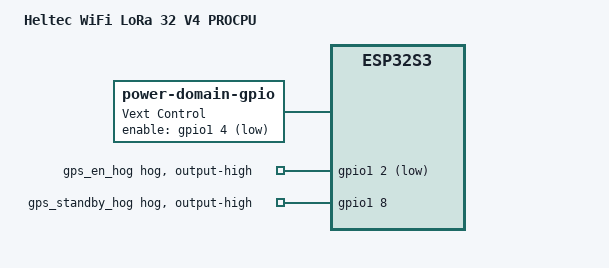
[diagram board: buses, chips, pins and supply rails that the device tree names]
/*
 * Heltec WiFi LoRa 32 (V4) — PROCPU, revisions 4.2 and 4.3.
 * ESP32-S3 WROOM, 16MB flash + 2MB QSPI PSRAM.
 *
 * SPDX-License-Identifier: Apache-2.0
 */
/dts-v1/;

#include <espressif/esp32s3/esp32s3.dtsi>
#include "heltec_wifi_lora32_v4-pinctrl.dtsi"
#include <zephyr/dt-bindings/pwm/pwm.h>
#include "heltec_partitions_16M.dtsi"
#include "heltec_wifi_lora32_v4-common.dtsi"

/*
 * The module's two facts, stated by the board. Until upstream Zephyr 8094e61
 * (2026-08-23) these came from espressif/esp32s3/esp32s3_wroom_n16r2.dtsi, which
 * that commit deleted along with every per-module dtsi. esp32s3.dtsi sets neither.
 * PSRAM *mode* and speed are in Kconfig.defconfig; only the size is here.
 */
&flash0 {
	reg = <0x0 DT_SIZE_M(16)>;
	ranges = <0x0 0x0 DT_SIZE_M(16)>;
};

&psram0 {
	size = <DT_SIZE_M(2)>;
};

/ {
	model = "Heltec WiFi LoRa 32 V4 PROCPU";
	compatible = "espressif,esp32s3";

	/*
	 * Vext (GPIO36, active-low) powers the OLED. The reference firmware drives
	 * it low at boot; here it is the OLED node's power-domain. On r8 this pin
	 * moves to GPIO40 — that board's .dts overrides enable-gpios.
	 */
	vext_ctrl: vext_ctrl {
		compatible = "power-domain-gpio";
		enable-gpios = <&gpio1 4 (GPIO_PULL_UP | GPIO_ACTIVE_LOW)>;	/* GPIO36 */
		#power-domain-cells = <0>;
		label = "Vext Control";
	};
};

/*
 * L76K GNSS control lines (4.2/4.3 pin-out). EN + STANDBY are held at their run
 * state by gpio-hogs; RESET is pulsed at boot from heltec_wifi_lora32_v4_fem.c
 * (mirroring firmware/src/gps/GPS.cpp, which resets the L76K at boot):
 *   EN      GPIO34 (gpio1.2) active-low  -> assert (enable)              [hog]
 *   STANDBY GPIO40 (gpio1.8) high = wake -> drive high (force wake)      [hog]
 *   RESET   GPIO42 (gpio1.10) active-low -> pulse low >=100ms, release   [C init]
 * VERIFY(hardware): confirm polarities against the L76K datasheet before trusting.
 */
&gpio1 {
	gps_en_hog {
		gpio-hog;
		gpios = <2 GPIO_ACTIVE_LOW>;	/* GPIO34, GPS_EN_ACTIVE=LOW */
		output-high;
	};

	gps_standby_hog {
		gpio-hog;
		gpios = <8 GPIO_ACTIVE_HIGH>;	/* GPIO40, high = force wake */
		output-high;
	};
};
